# XMC4300 register map
Vendor: Infineon; File version: 1.1.0 (Reference Manual v1.1)
CPU: CM4 r2p0, little endian, MPU, FPU, 6 interrupt priority bits
Registers are 32-bit, read-write, reset 0x0 unless marked. A register's access mark holds for its fields unless they carry their own. Offsets are from the block's base; [hi:lo] are bit positions; 'fields as' and 'values as' point back to an identical list.

## SCU_TRAP — System Control Unit
Base 0x50004160
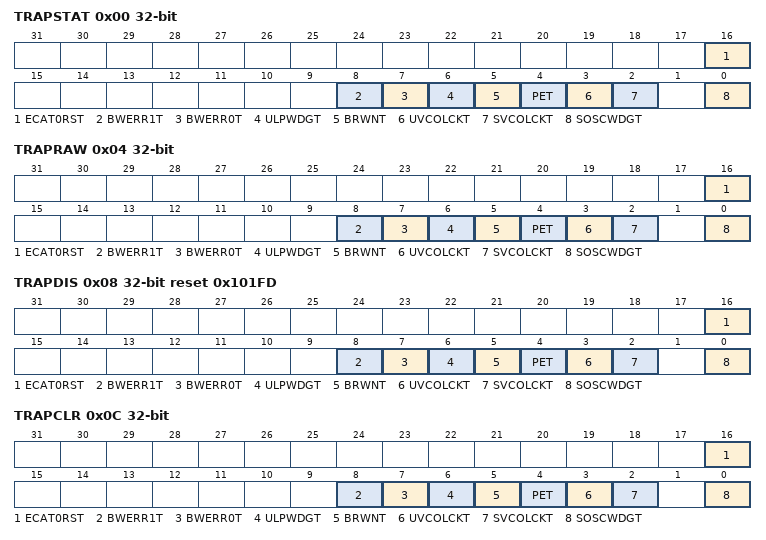
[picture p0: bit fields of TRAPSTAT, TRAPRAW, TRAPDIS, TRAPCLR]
0x00 TRAPSTAT ro — Trap Status Register
  [16] ECAT0RST — EtherCat Reset 0 Trap Status
    0=Const_0 (No effect); 1=Const_1 (Pending trap request)
  [8] BWERR1T — Peripheral Bridge 1 Trap Status
    0=Const_0 (No pending trap request); 1=Const_1 (Pending trap request)
  [7] BWERR0T — Peripheral Bridge 0 Trap Status
    values as BWERR1T
  [6] ULPWDGT — OSC_ULP Oscillator Watchdog Trap Status
    values as BWERR1T
  [5] BRWNT — Brown Out Trap Status
    values as BWERR1T
  [4] PET — Parity Error Trap Status
    values as BWERR1T
  [3] UVCOLCKT — USB VCO Lock Trap Status
    values as BWERR1T
  [2] SVCOLCKT — System VCO Lock Trap Status
    values as BWERR1T
  [0] SOSCWDGT — OSC_HP Oscillator Watchdog Trap Status
    values as BWERR1T
0x04 TRAPRAW ro — Trap Raw Status Register
  [all] fields
    values as TRAPSTAT.BWERR1T
  [16] ECAT0RST — EtherCat Reset 0 Trap Raw Status
  [8] BWERR1T — Peripheral Bridge 1 Trap Raw Status
  [7] BWERR0T — Peripheral Bridge 0 Trap Raw Status
  [6] ULPWDGT — OSC_ULP Oscillator Watchdog Trap Raw Status
  [5] BRWNT — Brown Out Trap Raw Status
  [4] PET — Parity Error Trap Raw Status
  [3] UVCOLCKT — USB VCO Lock Trap Raw Status
  [2] SVCOLCKT — System VCO Lock Trap Raw Status
  [0] SOSCWDGT — OSC_HP Oscillator Watchdog Trap Raw Status
0x08 TRAPDIS reset 0x101FD — Trap Disable Register
  [all] fields
    0=Const_0 (Trap request enabled); 1=Const_1 (Trap request disabled)
  [16] ECAT0RST — EtherCat Reset 0 Trap Disable
  [8] BWERR1T — Peripheral Bridge 1 Trap Disable
  [7] BWERR0T — Peripheral Bridge 0 Trap Disable
  [6] ULPWDGT — OSC_ULP Oscillator Watchdog Trap Disable
  [5] BRWNT — Brown Out Trap Disable
  [4] PET — Parity Error Trap Disable
  [3] UVCOLCKT — USB VCO Lock Trap Disable
  [2] SVCOLCKT — System VCO Lock Trap Disable
  [0] SOSCWDGT — OSC_HP Oscillator Watchdog Trap Disable
0x0C TRAPCLR wo — Trap Clear Register
  [16] ECAT0RST — EtherCat Reset 0 Trap Clear
    0=Const_0 (No effect); 1=Const_1 (Set trap request)
  [8] BWERR1T — Peripheral Bridge 1 Trap Clear
    0=Const_0 (No effect); 1=Const_1 (Clear trap request)
  [7] BWERR0T — Peripheral Bridge 0 Trap Clear
    0=Const_0 (No effect); 1=Const_1 (Clear trap request)
  [6] ULPWDGT — OSC_ULP Oscillator Watchdog Trap Clear
    0=Const_0 (No effect); 1=Const_1 (Clear trap request)
  [5] BRWNT — Brown Out Trap Clear
    0=Const_0 (No effect); 1=Const_1 (Clear trap request)
  [4] PET — Parity Error Trap Clear
    0=Const_0 (No effect); 1=Const_1 (Clear trap request)
  [3] UVCOLCKT — USB VCO Lock Trap Clear
    0=Const_0 (No effect); 1=Const_1 (Clear trap request)
  [2] SVCOLCKT — System VCO Lock Trap Clear
    0=Const_0 (No effect); 1=Const_1 (Clear trap request)
  [0] SOSCWDGT — OSC_HP Oscillator Watchdog Trap Clear
    0=Const_0 (No effect); 1=Const_1 (Clear trap request)
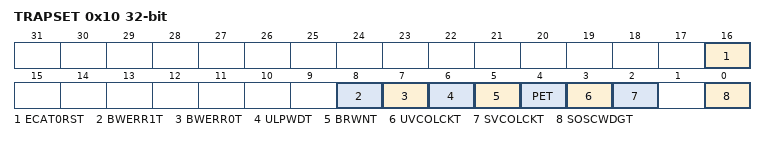
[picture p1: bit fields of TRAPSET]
0x10 TRAPSET wo
  [all] fields
    0=Const_0 (No effect); 1=Const_1 (Set trap request)
  [16] ECAT0RST — EtherCat Reset 0 Trap Set
  [8] BWERR1T — Peripheral Bridge 1 Trap Set
  [7] BWERR0T — Peripheral Bridge 0 Trap Set
  [6] ULPWDT — OSC_ULP Oscillator Watchdog Trap Set
  [5] BRWNT — Brown Out Trap Set
  [4] PET — Parity Error Trap Set
  [3] UVCOLCKT — USB VCO Lock Trap Set
  [2] SVCOLCKT — System VCO Lock Trap Set
  [0] SOSCWDGT — OSC_HP Oscillator Watchdog Trap Set

## SCU_POWER — System Control Unit
Base 0x50004200
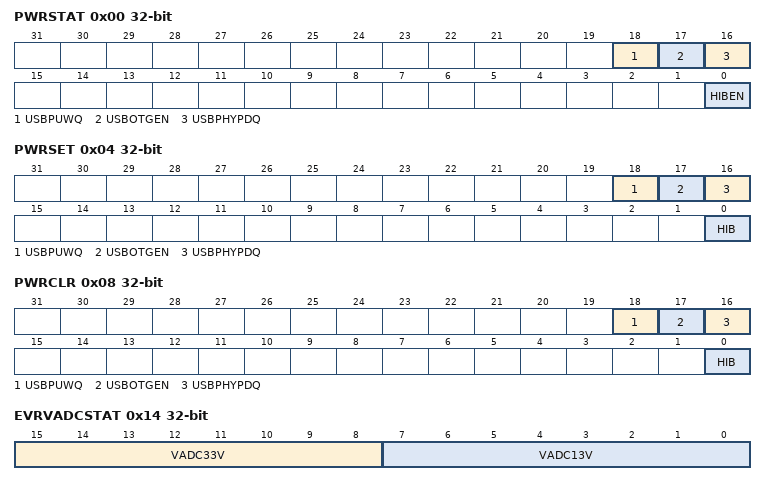
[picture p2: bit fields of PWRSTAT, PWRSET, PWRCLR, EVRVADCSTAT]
0x00 PWRSTAT ro — PCU Status Register
  [18] USBPUWQ — USB Weak Pull-Up at PADN State
    0=Const_0 (Pull-up active); 1=Const_1 (Pull-up not active)
  [17] USBOTGEN — USB On-The-Go Comparators State
    0=Const_0 (Power-down); 1=Const_1 (Active)
  [16] USBPHYPDQ — USB PHY Transceiver State
    0=Const_0 (Power-down); 1=Const_1 (Active)
  [0] HIBEN — Hibernate Domain Enable Status
    0=Const_0 (Inactive); 1=Const_1 (Active)
0x04 PWRSET wo — PCU Set Control Register
  [18] USBPUWQ — Set USB Weak Pull-Up at PADN Enable
    0=Const_0 (No effect); 1=Const_1 (Pull-up not active)
  [17] USBOTGEN — Set USB On-The-Go Comparators Enable
    0=Const_0 (No effect); 1=Const_1 (Active)
  [16] USBPHYPDQ — Set USB PHY Transceiver Disable
    0=Const_0 (No effect); 1=Const_1 (Active)
  [0] HIB — Set Hibernate Domain Enable
    0=Const_0 (No effect); 1=Const_1 (Enable Hibernate domain)
0x08 PWRCLR wo — PCU Clear Control Register
  [18] USBPUWQ — Clear USB Weak Pull-Up at PADN Enable
    0=Const_0 (No effect); 1=Const_1 (Pull-up active)
  [17] USBOTGEN — Clear USB On-The-Go Comparators Enable
    0=Const_0 (No effect); 1=Const_1 (Power-down)
  [16] USBPHYPDQ — Clear USB PHY Transceiver Disable
    0=Const_0 (No effect); 1=Const_1 (Power-down)
  [0] HIB — Clear Disable Hibernate Domain
    0=Const_0 (No effect); 1=Const_1 (Disable Hibernate domain)
0x10 EVRSTAT ro — EVR Status Register
  [1] OV13 — Regulator Overvoltage for 1.3 V
    0=Const_0 (No overvoltage condition); 1=Const_1 (Regulator is in overvoltage)
0x14 EVRVADCSTAT ro — EVR VADC Status Register
  [15:8] VADC33V — VADC 3.3 V Conversion Result
  [7:0] VADC13V — VADC 1.3 V Conversion Result
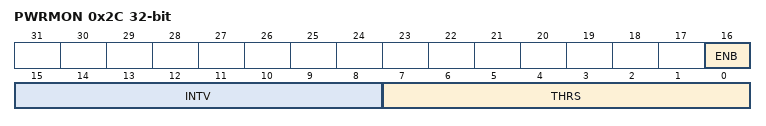
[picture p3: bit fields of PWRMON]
0x2C PWRMON — Power Monitor Control
  [16] ENB — Enable
  [15:8] INTV — Interval
  [7:0] THRS — Threshold
